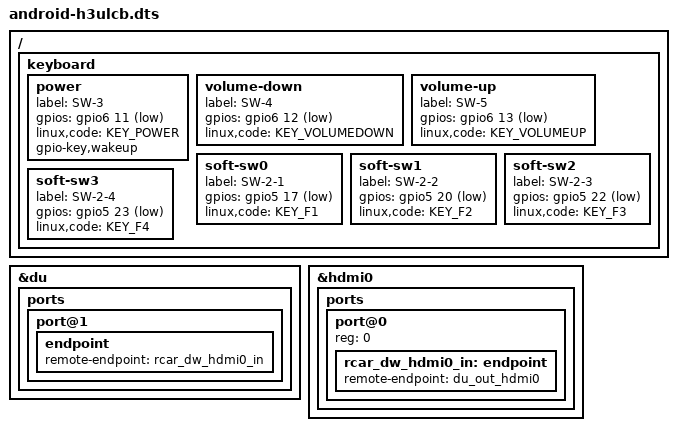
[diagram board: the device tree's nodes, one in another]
/*
 * Device Tree Source for the H3ULCB (R-Car Starter Kit Premier) board
 * Android specific extensions
 *
 * Copyright (C) 2018 GlobalLogic
 *
 * This file is licensed under the terms of the GNU General Public License
 * version 2.  This program is licensed "as is" without any warranty of any
 * kind, whether express or implied.
 */

#ifndef __H3ULCB_OVERWRITE__
#include "android-r8a7795-h3ulcb.dts"
#endif // __H3ULCB_OVERWRITE__
#include "android-h3.dtsi"

/ {
	keyboard {
		/delete-node/key-1;

		power {
			label = "SW-3";
			gpios = <&gpio6 11 GPIO_ACTIVE_LOW>;
			linux,code = <KEY_POWER>;
			gpio-key,wakeup;
		};

		volume-down {
			label = "SW-4";
			gpios = <&gpio6 12 GPIO_ACTIVE_LOW>;
			linux,code = <KEY_VOLUMEDOWN>;
		};

		volume-up {
			label = "SW-5";
			gpios = <&gpio6 13 GPIO_ACTIVE_LOW>;
			linux,code = <KEY_VOLUMEUP>;
		};

		soft-sw0 {
			label = "SW-2-1";
			gpios = <&gpio5 17 GPIO_ACTIVE_LOW>;
			linux,code = <KEY_F1>;
		};

		soft-sw1 {
			label = "SW-2-2";
			gpios = <&gpio5 20 GPIO_ACTIVE_LOW>;
			linux,code = <KEY_F2>;
		};

		soft-sw2 {
			label = "SW-2-3";
			gpios = <&gpio5 22 GPIO_ACTIVE_LOW>;
			linux,code = <KEY_F3>;
		};

		soft-sw3 {
			label = "SW-2-4";
			gpios = <&gpio5 23 GPIO_ACTIVE_LOW>;
			linux,code = <KEY_F4>;
		};
	};
};

&du {
	ports {
		port@1 {
			endpoint {
				remote-endpoint = <&rcar_dw_hdmi0_in>;
			};
		};
	};
};

&hdmi0 {
	ports {
		port@0 {
			reg = <0>;
			rcar_dw_hdmi0_in: endpoint {
				remote-endpoint = <&du_out_hdmi0>;
			};
		};
	};
};
